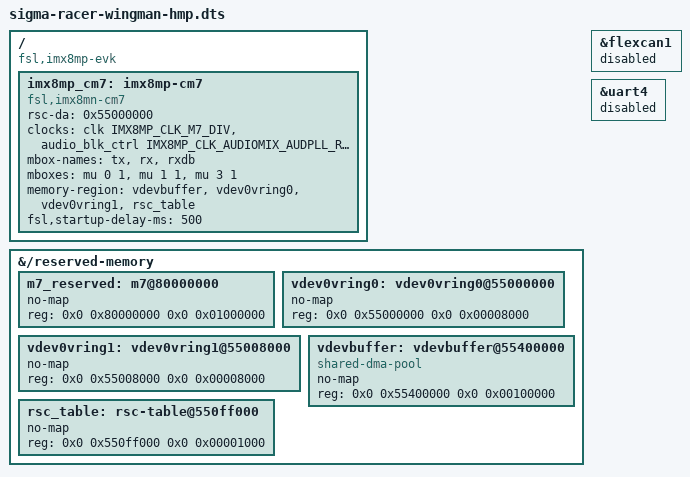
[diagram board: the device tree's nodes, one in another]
// Sigma Racer Wingman — heterogeneous multiprocessing overlay for the
// i.MX 8M Plus (NXP linux-imx BSP kernel). Applies on top of the stock
// imx8mp-evk devicetree and brings up the Cortex-M7 safety core as a Linux
// remoteproc so sigma-racer-sidearm.service can load sigma-racer-sidearm.elf
// onto it.
//
// Bindings mirror NXP's reference imx8mp-evk-rpmsg.dts (compatible
// "fsl,imx8mn-cm7", mailbox &mu, DDR carve-out at 0x80000000). The M7 is
// started by Linux (no U-Boot bootaux), so the node stays "okay" with no
// fsl,auto-boot and the remoteproc comes up OFFLINE for `echo start`.
/dts-v1/;
/plugin/;

#include <dt-bindings/clock/imx8mp-clock.h>

/ {
	compatible = "fsl,imx8mp-evk", "fsl,imx8mp";

	/* DDR carve-outs for the M7 image, vrings, vdev buffer and resource
	 * table. Cells inherit the base /reserved-memory (#address-cells = 2,
	 * #size-cells = 2). Must match the firmware linker map (memory.x:
	 * FLASH@0x80000000) and NXP's rsc-da below. */
	fragment@0 {
		target-path = "/reserved-memory";
		__overlay__ {
			m7_reserved: m7@80000000 {
				no-map;
				reg = <0x0 0x80000000 0x0 0x01000000>;
			};

			vdev0vring0: vdev0vring0@55000000 {
				no-map;
				reg = <0x0 0x55000000 0x0 0x00008000>;
			};

			vdev0vring1: vdev0vring1@55008000 {
				no-map;
				reg = <0x0 0x55008000 0x0 0x00008000>;
			};

			vdevbuffer: vdevbuffer@55400000 {
				compatible = "shared-dma-pool";
				no-map;
				reg = <0x0 0x55400000 0x0 0x00100000>;
			};

			rsc_table: rsc-table@550ff000 {
				no-map;
				reg = <0x0 0x550ff000 0x0 0x00001000>;
			};
		};
	};

	/* Cortex-M7 remoteproc node (NXP fsl,imx8mn-cm7 binding). Added as a
	 * top-level node — NXP defines it unlabeled at "/", not as a SoC-dtsi
	 * label, so there is no &imx8mp_cm7 to target. */
	fragment@1 {
		target-path = "/";
		__overlay__ {
			imx8mp_cm7: imx8mp-cm7 {
				compatible = "fsl,imx8mn-cm7";
				rsc-da = <0x55000000>;
				clocks = <&clk IMX8MP_CLK_M7_DIV>,
					 <&audio_blk_ctrl IMX8MP_CLK_AUDIOMIX_AUDPLL_ROOT>;
				clock-names = "core", "audio";
				mbox-names = "tx", "rx", "rxdb";
				mboxes = <&mu 0 1>, <&mu 1 1>, <&mu 3 1>;
				memory-region = <&vdevbuffer>, <&vdev0vring0>,
						<&vdev0vring1>, <&rsc_table>;
				fsl,startup-delay-ms = <500>;
				status = "okay";
			};
		};
	};

	/* FLEXCAN1 is owned by the M7 safety core — Linux uses FLEXCAN2 (can1). */
	fragment@2 {
		target = <&flexcan1>;
		__overlay__ {
			status = "disabled";
		};
	};

	/* UART4 is the M7 debug console — keep Linux off these pins. */
	fragment@3 {
		target = <&uart4>;
		__overlay__ {
			status = "disabled";
		};
	};
};
